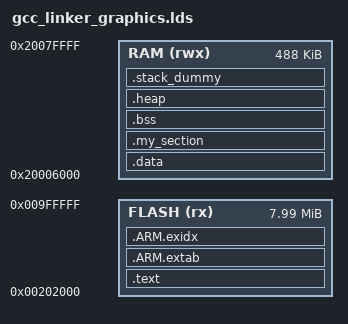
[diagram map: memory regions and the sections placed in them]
MEMORY
{
    FLASH (rx) : ORIGIN = 0x00202000, LENGTH = (0x00800000 -0x00002000)
    RAM (rwx)  : ORIGIN = 0x20000000 +0x6000, LENGTH = (0x00080000 -0x6000)
}

GROUP(libgcc.a libc.a libm.a libnosys.a)
ENTRY(Reset_Handler)

SECTIONS
{
    .text :
    {
        KEEP(*(.vectors))
        __Vectors_End = .;
        __Vectors_Size = __Vectors_End - __Vectors;
        __end__ = .;
        . = ALIGN(0x200);
        KEEP(*(.app_info));
        *( .text*)
        KEEP(*(.init))
        KEEP(*(.fini))
        *crtbegin.o(.ctors)
        *crtbegin?.o(.ctors)
        *(EXCLUDE_FILE(*crtend?.o *crtend.o) .ctors)
        *(SORT(.ctors.*))
        *(.ctors)
        *crtbegin.o(.dtors)
        *crtbegin?.o(.dtors)
        *(EXCLUDE_FILE(*crtend?.o *crtend.o) .dtors)
        *(SORT(.dtors.*))
        *(.dtors)
        *(.rodata*)
        KEEP(*(.eh_frame*))
    } > FLASH

    .ARM.extab :
    {
        *(.ARM.extab* .gnu.linkonce.armextab.*)
    } > FLASH

    __exidx_start = .;
    .ARM.exidx :
    {
        *(.ARM.exidx* .gnu.linkonce.armexidx.*)
    } > FLASH

    __exidx_end = .;
    __etext = .;

    .data : AT (__etext)
    {
        __data_start__ = .;
        *(vtable)
        *(.data*)
            *(RAM_CODE)

                . = ALIGN(4);
        PROVIDE_HIDDEN (__preinit_array_start = .);
        KEEP(*(.preinit_array))
        PROVIDE_HIDDEN (__preinit_array_end = .);
        . = ALIGN(4);
        PROVIDE_HIDDEN (__init_array_start = .);
        KEEP(*(SORT(.init_array.*)))
        KEEP(*(.init_array))
        PROVIDE_HIDDEN (__init_array_end = .);
        . = ALIGN(4);
        PROVIDE_HIDDEN (__fini_array_start = .);
        KEEP(*(SORT(.fini_array.*)))
        KEEP(*(.fini_array))
        PROVIDE_HIDDEN (__fini_array_end = .);
        KEEP(*(.jcr*))
        . = ALIGN(4);
        __data_end__ = .;
    } > RAM

    .my_section :
    {
        . = ALIGN(32);
        *(FPB*)
    } > RAM

    .bss :
    {
        . = ALIGN(4);
        __bss_start__ = .;
        *(.bss*)
        *(COMMON)
        . = ALIGN(4);
        __bss_end__ = .;
    } > RAM

    .heap (COPY):
    {
        __HeapBase = .;
        __end__ = .;
        end = __end__;
        KEEP(*(.heap*))
        __HeapLimit = .;
    } > RAM

    .stack_dummy (COPY):
    {
        KEEP(*(.stack*))
    } > RAM

    __StackTop = ORIGIN(RAM) + LENGTH(RAM);
    __StackLimit = __StackTop - SIZEOF(.stack_dummy);
    PROVIDE(__stack = __StackTop);
    ASSERT(__StackLimit >= __HeapLimit, "region RAM overflowed with stack")

    ASSERT(__StackTop <= 0x20080000, "stack overflowed with psram")

    /* GRAPHICS Memory space AREA                 */
    /* Notice 0x20880000 is the PSRAM end address */
    __GFX_MEM_HEAP_BASE = __StackTop + 0x10000000;
    __GFX_MEM_HEAP_END  = 0x30880000;
}
